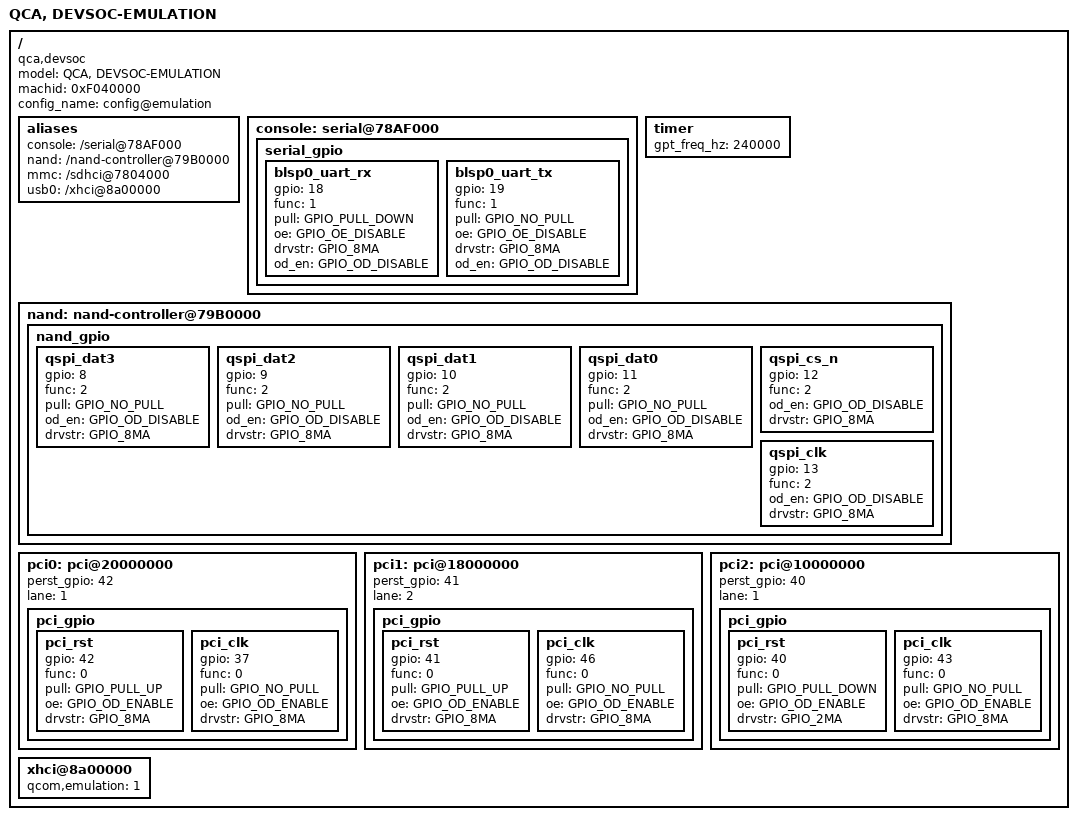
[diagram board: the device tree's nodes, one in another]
/*
 * Copyright (c) 2016-2019, The Linux Foundation. All rights reserved.
 *
 * Copyright (c) 2022 Qualcomm Innovation Center, Inc. All rights reserved.
 *
 * This program is free software; you can redistribute it and/or modify
 * it under the terms of the GNU General Public License version 2 and
 * only version 2 as published by the Free Software Foundation.
 *
 * This program is distributed in the hope that it will be useful,
 * but WITHOUT ANY WARRANTY; without even the implied warranty of
 * MERCHANTABILITY or FITNESS FOR A PARTICULAR PURPOSE.  See the
 * GNU General Public License for more details.
 */

/dts-v1/;
#include "devsoc-soc.dtsi"
/ {
	model ="QCA, DEVSOC-EMULATION";
	compatible = "qca,devsoc", "qca,devsoc-emulation";
	machid = <0xF040000>;
	config_name = "config@emulation";

	aliases {
		console = "/serial@78AF000";
		nand = "/nand-controller@79B0000";
		mmc = "/sdhci@7804000";
		usb0 = "/xhci@8a00000";
	};

	console: serial@78AF000 {
		status = "ok";
		serial_gpio {
			blsp0_uart_rx {
				gpio = <18>;
				func = <1>;
				pull = <GPIO_PULL_DOWN>;
				oe = <GPIO_OE_DISABLE>;
				drvstr = <GPIO_8MA>;
				od_en = <GPIO_OD_DISABLE>;
			};
			blsp0_uart_tx {
				gpio = <19>;
				func = <1>;
				pull = <GPIO_NO_PULL>;
				oe = <GPIO_OE_DISABLE>;
				drvstr = <GPIO_8MA>;
				od_en = <GPIO_OD_DISABLE>;
			};
		};
	};

	timer {
		gpt_freq_hz = <240000>;
	};

	nand: nand-controller@79B0000 {
		status = "okay";
		nand_gpio {
			qspi_dat3 {
				gpio = <8>;
				func = <2>;
				pull = <GPIO_NO_PULL>;
				od_en = <GPIO_OD_DISABLE>;
				drvstr = <GPIO_8MA>;
			};
			qspi_dat2 {
				gpio = <9>;
				func = <2>;
				pull = <GPIO_NO_PULL>;
				od_en = <GPIO_OD_DISABLE>;
				drvstr = <GPIO_8MA>;
			};
			qspi_dat1 {
				gpio = <10>;
				func = <2>;
				pull = <GPIO_NO_PULL>;
				od_en = <GPIO_OD_DISABLE>;
				drvstr = <GPIO_8MA>;
			};
			qspi_dat0 {
				gpio = <11>;
				func = <2>;
				pull = <GPIO_NO_PULL>;
				od_en = <GPIO_OD_DISABLE>;
				drvstr = <GPIO_8MA>;
			};
			qspi_cs_n {
				gpio = <12>;
				func = <2>;
				od_en = <GPIO_OD_DISABLE>;
				drvstr = <GPIO_8MA>;
			};
			qspi_clk {
				gpio = <13>;
				func = <2>;
				od_en = <GPIO_OD_DISABLE>;
				drvstr = <GPIO_8MA>;
			};
		};
	};

	pci0: pci@20000000 {
		status = "ok";
		perst_gpio = <42>;
		lane = <1>;
		pci_gpio {
			pci_rst {
				gpio = <42>;
				func = <0>;
				pull = <GPIO_PULL_UP>;
				oe = <GPIO_OD_ENABLE>;
				drvstr = <GPIO_8MA>;
			};
			pci_clk {
				gpio = <37>;
				func = <0>;
				pull = <GPIO_NO_PULL>;
				oe = <GPIO_OD_ENABLE>;
				drvstr = <GPIO_8MA>;
			};
		};
	};

	pci1: pci@18000000 {
		status = "ok";
		perst_gpio = <41>;
		lane = <2>;
		pci_gpio {
			pci_rst {
				gpio = <41>;
				func = <0>;
				pull = <GPIO_PULL_UP>;
				oe = <GPIO_OD_ENABLE>;
				drvstr = <GPIO_8MA>;
			};
			pci_clk {
				gpio = <46>;
				func = <0>;
				pull = <GPIO_NO_PULL>;
				oe = <GPIO_OD_ENABLE>;
				drvstr = <GPIO_8MA>;
			};
		};
	};

	pci2: pci@10000000 {
		status = "ok";
		perst_gpio = <40>;
		lane = <1>;
		pci_gpio {
			pci_rst {
				gpio = <40>;
				func = <0>;
				pull = <GPIO_PULL_DOWN>;
				oe = <GPIO_OD_ENABLE>;
				drvstr = <GPIO_2MA>;
			};
			pci_clk {
				gpio = <43>;
				func = <0>;
				pull = <GPIO_NO_PULL>;
				oe = <GPIO_OD_ENABLE>;
				drvstr = <GPIO_8MA>;
			};
		};
	};

	xhci@8a00000 {
		qcom,emulation = <1>;
	};
};
